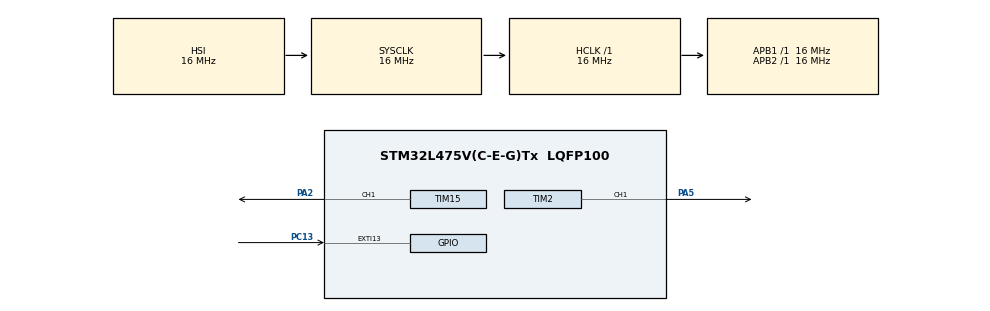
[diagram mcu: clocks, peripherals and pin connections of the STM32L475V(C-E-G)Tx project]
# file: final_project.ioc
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Mcu.Family=STM32L4
Mcu.Name=STM32L475V(C-E-G)Tx
Mcu.Package=LQFP100
NVIC.EXTI15_10_IRQn=true\:0\:0\:false\:false\:true\:true\:true
NVIC.PriorityGroup=NVIC_PRIORITYGROUP_4
NVIC.TIM1_TRG_COM_TIM17_IRQn=true\:15\:0\:false\:false\:true\:false\:true
NVIC.TimeBase=TIM1_TRG_COM_TIM17_IRQn
NVIC.TimeBaseIP=TIM17
PA2.Signal=S_TIM15_CH1
PA5.Signal=S_TIM2_CH1
PC13.Signal=GPXTI13
ProjectManager.HeapSize=0x200
ProjectManager.StackSize=0x400
ProjectManager.TargetToolchain=EWARM V8.32
RCC.AHBFreq_Value=16000000
RCC.APB1Freq_Value=16000000
RCC.APB1TimFreq_Value=16000000
RCC.APB2Freq_Value=16000000
RCC.APB2TimFreq_Value=16000000
RCC.CortexFreq_Value=16000000
RCC.HCLKFreq_Value=16000000
RCC.HSE_VALUE=8000000
RCC.HSI_VALUE=16000000
RCC.LSE_VALUE=32768
RCC.MSI_VALUE=4000000
RCC.SYSCLKFreq_VALUE=16000000
RCC.SYSCLKSource=RCC_SYSCLKSOURCE_HSI
RCC.VCOOutputFreq_Value=32000000
SH.S_TIM15_CH1.0=TIM15_CH1,PWM Generation1 CH1
SH.S_TIM2_CH1.0=TIM2_CH1,PWM Generation1 CH1
TIM15.Channel-PWM\ Generation1\ CH1=TIM_CHANNEL_1
TIM15.Period=2000-1
TIM15.Prescaler=160-1
TIM2.Channel-PWM\ Generation1\ CH1=TIM_CHANNEL_1
TIM2.Period=2000-1
TIM2.Prescaler=160-1
VP_SYS_VS_tim17.Mode=TIM17
VP_TIM15_VS_ClockSourceINT.Mode=Internal
VP_TIM2_VS_ClockSourceINT.Mode=Internal
board=custom

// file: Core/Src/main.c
/* USER CODE BEGIN Header */
/**
  ******************************************************************************
  * @file           : main.c
  * @brief          : Main program body
  ******************************************************************************
  * @attention
  *
  * <h2><center>&copy; Copyright (c) 2021 STMicroelectronics.
  * All rights reserved.</center></h2>
  *
  * This software component is licensed by ST under BSD 3-Clause license,
  * the "License"; You may not use this file except in compliance with the
  * License. You may obtain a copy of the License at:
  *                        opensource.org/licenses/BSD-3-Clause
  *
  ******************************************************************************
  */
/* USER CODE END Header */
#include "main.h"

/* USER CODE BEGIN Includes */
#include "led_states.h"
/* USER CODE END Includes */

TIM_HandleTypeDef htim2;
TIM_HandleTypeDef htim15;

/* USER CODE BEGIN PV */
volatile uint8_t current_state = RESET_OFF;
/* USER CODE END PV */

void SystemClock_Config(void);
static void MX_GPIO_Init(void);
static void MX_TIM2_Init(void);
static void MX_TIM15_Init(void);
/* USER CODE BEGIN PFP */
void user_pwm_setvalue(uint16_t value)
{
    TIM_OC_InitTypeDef sConfigOC;

    sConfigOC.OCMode = TIM_OCMODE_PWM1;
    sConfigOC.Pulse = value;
    sConfigOC.OCPolarity = TIM_OCPOLARITY_HIGH;
    sConfigOC.OCFastMode = TIM_OCFAST_DISABLE;
    HAL_TIM_PWM_ConfigChannel(&htim2, &sConfigOC, TIM_CHANNEL_1);
    HAL_TIM_PWM_Start(&htim2, TIM_CHANNEL_1);
}
/* USER CODE END PFP */

int main(void)
{

  /* MCU Configuration--------------------------------------------------------*/

  /* Reset of all peripherals, Initializes the Flash interface and the Systick. */
  HAL_Init();

  /* Configure the system clock */
  SystemClock_Config();

  /* Initialize all configured peripherals */
  MX_GPIO_Init();
  MX_TIM2_Init();
  MX_TIM15_Init();
  /* USER CODE BEGIN 2 */
  volatile uint16_t counter = 0;
  uint16_t pwm_value = 0;
  int16_t step = 0;
  HAL_TIM_PWM_Start(&htim2, TIM_CHANNEL_1);
  HAL_TIM_PWM_Start(&htim15, TIM_CHANNEL_1);
  /* USER CODE END 2 */

  /* Infinite loop */
  while (1)
  {

    /* USER CODE BEGIN 3 */
    if(current_state == RESET_OFF)
    {
      GPIOA->MODER |= GPIO_MODER_MODE5_0;
      GPIOA->MODER &= ~GPIO_MODER_MODE5_1;

      GPIOA->MODER |= GPIO_MODER_MODE14_0;
      GPIOA->MODER &= ~GPIO_MODER_MODE14_1;

      GPIOA->ODR &= GPIO_ODR_OD5;
      GPIOB->ODR &= GPIO_ODR_OD14;
    }
    else if(current_state == ON_SOLID)
    {
      GPIOA->MODER |= GPIO_MODER_MODE5_0;
      GPIOA->MODER &= ~GPIO_MODER_MODE5_1;

      GPIOA->MODER |= GPIO_MODER_MODE14_0;
      GPIOA->MODER &= ~GPIO_MODER_MODE14_1;

      GPIOA->ODR |= GPIO_ODR_OD5;
      GPIOB->ODR |= GPIO_ODR_OD14;
    }
    else if(current_state == BLINK_SLOW)
    {
      GPIOA->MODER |= GPIO_MODER_MODE5_0;
      GPIOA->MODER &= ~GPIO_MODER_MODE5_1;

      GPIOA->MODER |= GPIO_MODER_MODE14_0;
      GPIOA->MODER &= ~GPIO_MODER_MODE14_1;

      GPIOA->ODR ^= GPIO_ODR_OD5;
      GPIOB->ODR ^= GPIO_ODR_OD14;
    }
    else if(current_state == BLINK_FAST)
    {
      GPIOA->MODER |= GPIO_MODER_MODE5_0;
      GPIOA->MODER &= ~GPIO_MODER_MODE5_1;

      GPIOA->MODER |= GPIO_MODER_MODE14_0;
      GPIOA->MODER &= ~GPIO_MODER_MODE14_1;

      GPIOA->ODR ^= ~GPIO_ODR_OD5;
      GPIOB->ODR ^= ~GPIO_ODR_OD14;
      HAL_Delay(100);
    }
    else if(current_state == DIM_SLOW)
    {
      GPIOA->MODER &= ~GPIO_MODER_MODE5_0;
      GPIOA->MODER |= GPIO_MODER_MODE5_1;

      GPIOA->AFR[0] &= ~GPIO_AFRL_AFSEL5_Msk;
      GPIOA->AFR[0] |= GPIO_AFRL_AFSEL5_0;

      GPIOA->MODER &= ~GPIO_MODER_MODE14_0;
      GPIOA->MODER |= GPIO_MODER_MODE14_1;

      GPIOA->AFR[1] &= ~GPIO_AFRH_AFSEL14_Msk;
      GPIOA->AFR[1] |= GPIO_AFRH_AFSEL14_1;
      GPIOA->AFR[1] |= GPIO_AFRH_AFSEL14_2;
      GPIOA->AFR[1] |= GPIO_AFRH_AFSEL14_3;

      HAL_Delay(50);
      if(pwm_value == 0) step = 100;
      if(pwm_value == 2000) step = -100;
      pwm_value += step;
      user_pwm_setvalue(pwm_value);
    }
    else if(current_state == DIM_FAST)
    {
      GPIOA->MODER &= ~GPIO_MODER_MODE5_0;
      GPIOA->MODER |= GPIO_MODER_MODE5_1;

      GPIOA->AFR[0] &= ~GPIO_AFRL_AFSEL5_Msk;
      GPIOA->AFR[0] |= GPIO_AFRL_AFSEL5_0;

      GPIOA->MODER &= ~GPIO_MODER_MODE14_0;
      GPIOA->MODER |= GPIO_MODER_MODE14_1;

      GPIOA->AFR[1] &= ~GPIO_AFRH_AFSEL14_Msk;
      GPIOA->AFR[1] |= GPIO_AFRH_AFSEL14_1;
      GPIOA->AFR[1] |= GPIO_AFRH_AFSEL14_2;
      GPIOA->AFR[1] |= GPIO_AFRH_AFSEL14_3;

      HAL_Delay(25);
      if(pwm_value == 0) step = 500;
      if(pwm_value == 2000) step = -500;
      pwm_value += step;
      user_pwm_setvalue(pwm_value);
    }
    //HAL_Delay(1000);
    /*
    if((GPIOC->IDR & GPIO_IDR_ID13) == 0)
    {
      GPIOA->ODR ^= GPIO_ODR_OD5;
      GPIOB->ODR ^= GPIO_ODR_OD14;
    }
    */
    /*

    GPIO_PinState val = HAL_GPIO_ReadPin(GPIOC, GPIO_PIN_13);
    if(val != GPIO_PIN_SET)
    {
      HAL_Delay(1000);
      HAL_GPIO_TogglePin(GPIOB, GPIO_PIN_14);
      HAL_GPIO_TogglePin(GPIOA, GPIO_PIN_5);
      counter++;
    }
    */
  }
  /* USER CODE END 3 */
}

void SystemClock_Config(void)
{
  RCC_OscInitTypeDef RCC_OscInitStruct = {0};
  RCC_ClkInitTypeDef RCC_ClkInitStruct = {0};

  /** Configure the main internal regulator output voltage
  */
  if (HAL_PWREx_ControlVoltageScaling(PWR_REGULATOR_VOLTAGE_SCALE1) != HAL_OK)
  {
    Error_Handler();
  }
  /** Initializes the RCC Oscillators according to the specified parameters
  * in the RCC_OscInitTypeDef structure.
  */
  RCC_OscInitStruct.OscillatorType = RCC_OSCILLATORTYPE_HSI;
  RCC_OscInitStruct.HSIState = RCC_HSI_ON;
  RCC_OscInitStruct.HSICalibrationValue = RCC_HSICALIBRATION_DEFAULT;
  RCC_OscInitStruct.PLL.PLLState = RCC_PLL_NONE;
  if (HAL_RCC_OscConfig(&RCC_OscInitStruct) != HAL_OK)
  {
    Error_Handler();
  }
  /** Initializes the CPU, AHB and APB buses clocks
  */
  RCC_ClkInitStruct.ClockType = RCC_CLOCKTYPE_HCLK|RCC_CLOCKTYPE_SYSCLK
                              |RCC_CLOCKTYPE_PCLK1|RCC_CLOCKTYPE_PCLK2;
  RCC_ClkInitStruct.SYSCLKSource = RCC_SYSCLKSOURCE_HSI;
  RCC_ClkInitStruct.AHBCLKDivider = RCC_SYSCLK_DIV1;
  RCC_ClkInitStruct.APB1CLKDivider = RCC_HCLK_DIV1;
  RCC_ClkInitStruct.APB2CLKDivider = RCC_HCLK_DIV1;

  if (HAL_RCC_ClockConfig(&RCC_ClkInitStruct, FLASH_LATENCY_0) != HAL_OK)
  {
    Error_Handler();
  }
}

static void MX_TIM2_Init(void)
{

  TIM_ClockConfigTypeDef sClockSourceConfig = {0};
  TIM_MasterConfigTypeDef sMasterConfig = {0};
  TIM_OC_InitTypeDef sConfigOC = {0};

  htim2.Instance = TIM2;
  htim2.Init.Prescaler = 160-1;
  htim2.Init.CounterMode = TIM_COUNTERMODE_UP;
  htim2.Init.Period = 2000-1;
  htim2.Init.ClockDivision = TIM_CLOCKDIVISION_DIV1;
  htim2.Init.AutoReloadPreload = TIM_AUTORELOAD_PRELOAD_DISABLE;
  if (HAL_TIM_Base_Init(&htim2) != HAL_OK)
  {
    Error_Handler();
  }
  sClockSourceConfig.ClockSource = TIM_CLOCKSOURCE_INTERNAL;
  if (HAL_TIM_ConfigClockSource(&htim2, &sClockSourceConfig) != HAL_OK)
  {
    Error_Handler();
  }
  if (HAL_TIM_PWM_Init(&htim2) != HAL_OK)
  {
    Error_Handler();
  }
  sMasterConfig.MasterOutputTrigger = TIM_TRGO_RESET;
  sMasterConfig.MasterSlaveMode = TIM_MASTERSLAVEMODE_DISABLE;
  if (HAL_TIMEx_MasterConfigSynchronization(&htim2, &sMasterConfig) != HAL_OK)
  {
    Error_Handler();
  }
  sConfigOC.OCMode = TIM_OCMODE_PWM1;
  sConfigOC.Pulse = 0;
  sConfigOC.OCPolarity = TIM_OCPOLARITY_HIGH;
  sConfigOC.OCFastMode = TIM_OCFAST_DISABLE;
  if (HAL_TIM_PWM_ConfigChannel(&htim2, &sConfigOC, TIM_CHANNEL_1) != HAL_OK)
  {
    Error_Handler();
  }
  HAL_TIM_MspPostInit(&htim2);

}

static void MX_TIM15_Init(void)
{

  TIM_ClockConfigTypeDef sClockSourceConfig = {0};
  TIM_MasterConfigTypeDef sMasterConfig = {0};
  TIM_OC_InitTypeDef sConfigOC = {0};
  TIM_BreakDeadTimeConfigTypeDef sBreakDeadTimeConfig = {0};

  htim15.Instance = TIM15;
  htim15.Init.Prescaler = 160-1;
  htim15.Init.CounterMode = TIM_COUNTERMODE_UP;
  htim15.Init.Period = 2000-1;
  htim15.Init.ClockDivision = TIM_CLOCKDIVISION_DIV1;
  htim15.Init.RepetitionCounter = 0;
  htim15.Init.AutoReloadPreload = TIM_AUTORELOAD_PRELOAD_DISABLE;
  if (HAL_TIM_Base_Init(&htim15) != HAL_OK)
  {
    Error_Handler();
  }
  sClockSourceConfig.ClockSource = TIM_CLOCKSOURCE_INTERNAL;
  if (HAL_TIM_ConfigClockSource(&htim15, &sClockSourceConfig) != HAL_OK)
  {
    Error_Handler();
  }
  if (HAL_TIM_PWM_Init(&htim15) != HAL_OK)
  {
    Error_Handler();
  }
  sMasterConfig.MasterOutputTrigger = TIM_TRGO_RESET;
  sMasterConfig.MasterSlaveMode = TIM_MASTERSLAVEMODE_DISABLE;
  if (HAL_TIMEx_MasterConfigSynchronization(&htim15, &sMasterConfig) != HAL_OK)
  {
    Error_Handler();
  }
  sConfigOC.OCMode = TIM_OCMODE_PWM1;
  sConfigOC.Pulse = 0;
  sConfigOC.OCPolarity = TIM_OCPOLARITY_HIGH;
  sConfigOC.OCNPolarity = TIM_OCNPOLARITY_HIGH;
  sConfigOC.OCFastMode = TIM_OCFAST_DISABLE;
  sConfigOC.OCIdleState = TIM_OCIDLESTATE_RESET;
  sConfigOC.OCNIdleState = TIM_OCNIDLESTATE_RESET;
  if (HAL_TIM_PWM_ConfigChannel(&htim15, &sConfigOC, TIM_CHANNEL_1) != HAL_OK)
  {
    Error_Handler();
  }
  sBreakDeadTimeConfig.OffStateRunMode = TIM_OSSR_DISABLE;
  sBreakDeadTimeConfig.OffStateIDLEMode = TIM_OSSI_DISABLE;
  sBreakDeadTimeConfig.LockLevel = TIM_LOCKLEVEL_OFF;
  sBreakDeadTimeConfig.DeadTime = 0;
  sBreakDeadTimeConfig.BreakState = TIM_BREAK_DISABLE;
  sBreakDeadTimeConfig.BreakPolarity = TIM_BREAKPOLARITY_HIGH;
  sBreakDeadTimeConfig.AutomaticOutput = TIM_AUTOMATICOUTPUT_DISABLE;
  if (HAL_TIMEx_ConfigBreakDeadTime(&htim15, &sBreakDeadTimeConfig) != HAL_OK)
  {
    Error_Handler();
  }
  HAL_TIM_MspPostInit(&htim15);

}

static void MX_GPIO_Init(void)
{
  GPIO_InitTypeDef GPIO_InitStruct = {0};

  /* GPIO Ports Clock Enable */
  __HAL_RCC_GPIOC_CLK_ENABLE();
  __HAL_RCC_GPIOA_CLK_ENABLE();

  /*Configure GPIO pin : PC13 */
  GPIO_InitStruct.Pin = GPIO_PIN_13;
  GPIO_InitStruct.Mode = GPIO_MODE_IT_RISING;
  GPIO_InitStruct.Pull = GPIO_NOPULL;
  HAL_GPIO_Init(GPIOC, &GPIO_InitStruct);

  /* EXTI interrupt init*/
  HAL_NVIC_SetPriority(EXTI15_10_IRQn, 0, 0);
  HAL_NVIC_EnableIRQ(EXTI15_10_IRQn);

}

void HAL_TIM_PeriodElapsedCallback(TIM_HandleTypeDef *htim)
{
  if (htim->Instance == TIM17) {
    HAL_IncTick();
  }
}

void Error_Handler(void)
{
  __disable_irq();
  while (1)
  {
  }
}

/************************ (C) COPYRIGHT STMicroelectronics *****END OF FILE****/
